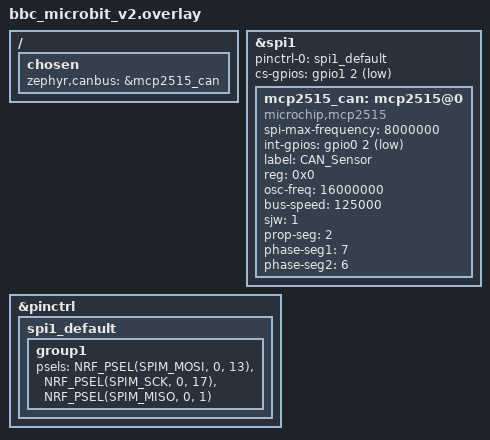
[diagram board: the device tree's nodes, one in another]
&spi1 {
	status = "okay";
	pinctrl-0 = <&spi1_default>;
	pinctrl-names = "default";
	cs-gpios = <&gpio1 2 GPIO_ACTIVE_LOW>;
	mcp2515_can: mcp2515@0 {
		compatible = "microchip,mcp2515";
        spi-max-frequency = <8000000>;
        int-gpios = <&gpio0 2 GPIO_ACTIVE_LOW>;
        status = "okay";
		label = "CAN_Sensor";
		reg = <0x0>;
		osc-freq = <16000000>;
		bus-speed = <125000>;
		sjw = <1>;
		prop-seg = <2>;
		phase-seg1 = <7>;
		phase-seg2 = <6>;
		#address-cells = <1>;
		#size-cells = <0>;

	};


};

&pinctrl {
	spi1_default: spi1_default {
		group1 {
			psels = <NRF_PSEL(SPIM_MOSI, 0, 13)>,
					<NRF_PSEL(SPIM_SCK, 0, 17)>,
					<NRF_PSEL(SPIM_MISO, 0, 1)>;
		};
	};
};

/ {
    chosen {
        zephyr,canbus = &mcp2515_can;
    };
};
